# COMPUTE_CLUSTER0_DRU register map
Vendor: Texas Instruments
Peripheral module from a debugger description file (folder am65x).
Registers are 64-bit, read-write, reset 0x0 unless marked. A register's access mark holds for its fields unless they carry their own. Offsets are as the file gives them; lines under a group give offsets from that group; [hi:lo] are bit positions; {n}, {i} and the like mark numbered series; 'fields as' and 'values as' point back to an identical list; <NAME> marks a mode.

## COMPUTE_CLUSTER0_DRU
0x00 DRU_PID ro reset 0x662C0900 — Peripheral ID Register
  [31:0] REVISION — PID Revision
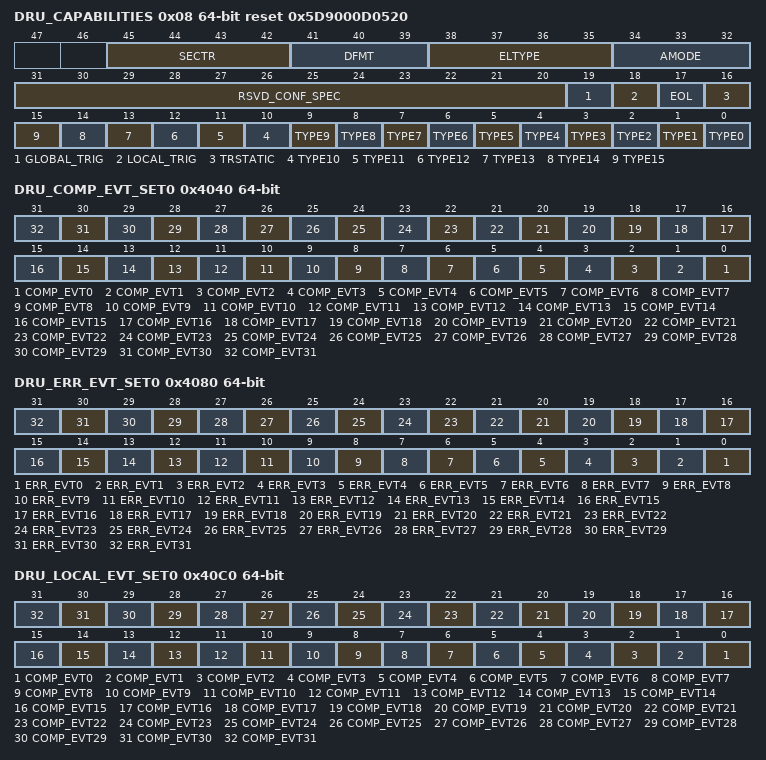
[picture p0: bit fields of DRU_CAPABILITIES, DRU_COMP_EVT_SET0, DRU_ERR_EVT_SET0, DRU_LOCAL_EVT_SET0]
0x08 DRU_CAPABILITIES ro reset 0x5D9000D0520 — DRU Capabilities: Lists the capabilities of the channel for TR TYPE and formatting functions
  [45:42] SECTR — Maximum second TR function that is supported
  [41:39] DFMT — Maximum data reformatting function that is supported
  [38:35] ELTYPE — Maximum element type value that is supported
  [34:32] AMODE — The maximum AMODE that is supported. If AMODE is supported then DIR field must be supported for that AMODE.
  [31:20] RSVD_CONF_SPEC — Reserved for Configuration Specific Features. This implementation has no configuration specific features.
  [19] GLOBAL_TRIG — Global Triggers 0 and 1 are supported
  [18] LOCAL_TRIG — Dedicated Local Trigger is supported
  [17] EOL — EOL Field is supported
  [16] TRSTATIC — STATIC Field is supported
  [n] TYPE{n} (n=0..15) — Type {n} TR is supported
0x4000 DRU_SHARED_EVT_SET access per field — DRU Shared Event Set Register
  [0] PROT_ERR wo — Set the protocol error event
0x4040 DRU_COMP_EVT_SET0 wo — DRU Completion Event Set Register
  [n] COMP_EVT{n} (n=0..31) — Set the Completion Event for channel {n}
0x4080 DRU_ERR_EVT_SET0 wo — DRU Error Event Set Register
  [n] ERR_EVT{n} (n=0..31) — Set the Error Event for channel {n}
0x40C0 DRU_LOCAL_EVT_SET0 wo — DRU Local Event Set Register
  [n] COMP_EVT{n} (n=0..31) — Set the Local Event for channel {n}
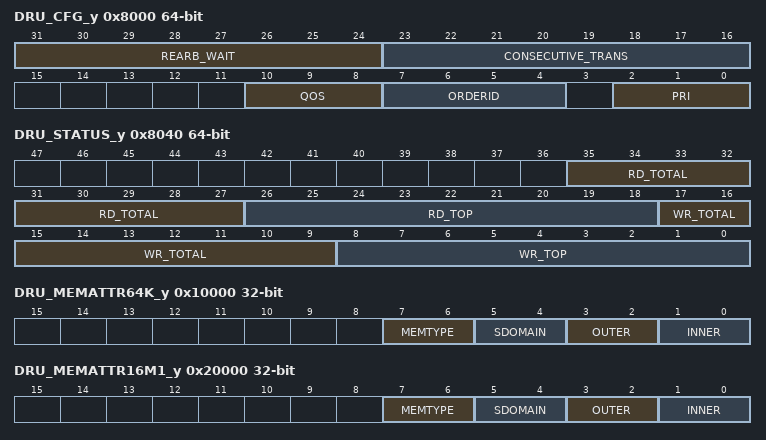
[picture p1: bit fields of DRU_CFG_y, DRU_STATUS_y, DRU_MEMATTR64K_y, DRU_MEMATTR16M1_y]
0x8000 DRU_CFG_y access per field — Configuration Register for Queue 'y' Offset = 8000h + (y * 8h); where y = 0h to 4h
  [31:24] REARB_WAIT rw — This is the number of commands that will be sent by other queues before allowing the queue to arbitrate again for the right to send commands. This is only started when a queue exhausted its consecutive trans count.
  [23:16] CONSECUTIVE_TRANS rw — This is the number of consecutive transactions that will be sent before allowing another queue of equal level to arbitrate to send commands. This is the maximum number of commands that it can send. If the queue has any delays such as virtual address lookup then the arbitration will be forced regardless of the number of commands.
  [10:8] QOS rw — This configures the QoS for Queue 'y'. This should only be set for fixed priority queues and the lower queue should have the lower QoS.
  [7:4] ORDERID rw — This configures the Order ID for Queue 'y'.
  [2:0] PRI rw — This configures the priority for Queue 'y'. This will be the priority that will be presented on the External bus for all commands from this queue.
0x8040 DRU_STATUS_y ro — Status Register for Queue 'y' Offset = 8040h + (y * 8h); where y = 0h to 4h
  [35:27] RD_TOTAL — This is the channel that the read half is currently working on.
  [26:18] RD_TOP — This is the channel that the read half is currently working on.
  [17:9] WR_TOTAL — This is the channel that the write half is currently working on.
  [8:0] WR_TOP — This is the channel that the write half is currently working on.
0x10000 DRU_MEMATTR64K_y 32-bit — The Memory Attribute register contains the attributes for all the 64K mapped regions. Offset = 10000h + (y * 4h); where y = 0h to 7Fh
  [7:6] MEMTYPE — Defines the type of the memory
  [5:4] SDOMAIN — Defines the shareability domain of the memory
  [3:2] OUTER — Defines the outer allocatability of the memory
  [1:0] INNER — Defines the inner allocatability of the memory
0x20000 DRU_MEMATTR16M1_y 32-bit — The Memory Attribute register contains the attributes for all the second 16M mapped regions. Offset = 20000h + (y * 4h); where y = 0h to 7FFh
  fields as DRU_MEMATTR64K_y
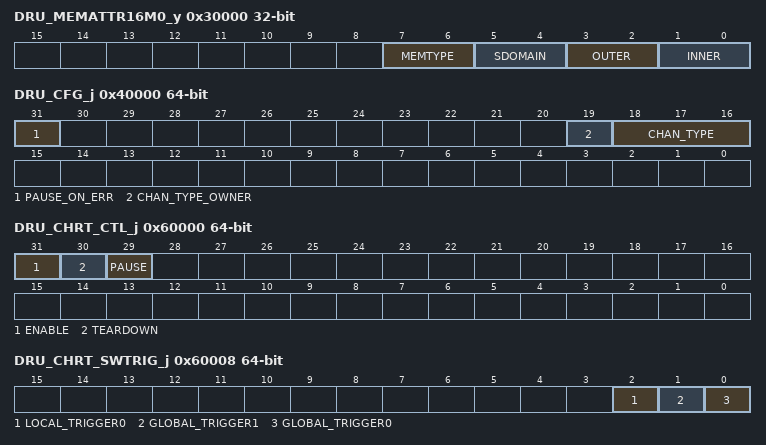
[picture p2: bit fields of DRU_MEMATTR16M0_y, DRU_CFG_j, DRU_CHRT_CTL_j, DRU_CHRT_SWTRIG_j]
0x30000 DRU_MEMATTR16M0_y 32-bit — The Memory Attribute register contains the attributes for all the first 16M mapped regions. Offset = 30000h + (y * 4h); where y = 0h to 7Fh
  fields as DRU_MEMATTR64K_y
0x40000 DRU_CFG_j access per field — Channel Configuration Register. The Channel Configuration Register is used to initialize static mode settings for the DMA Channel. The register may only be written when the chanel is disable by setting to 0x0 the DRU_CHRT_CTL_j[31] ENABLE bit. Offset = 40000h + (j * 100h); where j = 0h to 1Fh
  [31] PAUSE_ON_ERR rw — Pause on Error. This field controls what the channel will do if an error or exception occurs during a data transfer. This field is encoded as follows:0 = Channel will drop current work and move on1 = Channel will pause and wait for SW to investigate and un-pause the channel.
  [19] CHAN_TYPE_OWNER rw — This field controls how the TR is received by the UTC.0 = The DRU_SUBMIT_WORD0_1_j_k to DRU_SUBMIT_WORD14_15_j_k registers must be written to submit it.1 = The TR will be received through PSI-L.
  [18:16] CHAN_TYPE ro — This field states the TR type that is being used along with CHAN_TYPE_OWNER field make up the 4-bit CHAN_TYPE for an UTC. The value of this is all zeroes to reflect that the UTC DRU only does TRs through pass-by value mechanisms.
0x40020 DRU_CHOES0_j access per field — The Output Event Steering Registers are used to specify a global event number to generate anytime the required event generation criteria specified in a TR are met. A single event with the event number set equal to the value in the corresponding register will be generated. This register is provided in order to allow security software to lock down which events in the global space any given channel/ thread is allowed to generate Offset = 40020h + (j * 100h); where j = 0h to 1Fh
  [15:0] EVT_NUM rw — This is the global event number to be generated.
0x40060 DRU_CHST_SCHED_j — Channel Static Scheduler Config Register Offset = 40060h + (j * 100h); where j = 0h to 1Fh
  [2:0] QUEUE — Thus is the queue number that is written
0x60000 DRU_CHRT_CTL_j access per field — The channel realtime control register contains real-time cotrol and status information for the DMA Channel. The fields in this regsiter can be changed while the channel is in operation. Offset = 60000h + (j * 100h); where j = 0h to 1Fh
  [31] ENABLE rw — This field enables or disables the channel. Disabling a channel halts operation on the channel after the current block transfer is completed. Disabling a channel in the middle of a packet transfer may result in underflow conditions in the attached application block and data loss. This field will be cleared after a channel teardown is complete. This field is encoded as follows:0 = channel is disabled1 = channel is enabled
  [30] TEARDOWN rw — Channel teardown.Setting this bit will request the channel to be torn down. This field will remain set after a channel teardown is complete.
  [29] PAUSE rw — Channel pause.Setting this bit will request the channel to pause processing at the next packet boundary. This is a more graceful method of halting processing than disabling the channel as it will not allow any current packets to underflow.
0x60008 DRU_CHRT_SWTRIG_j access per field — The Software Trigger Register provides a mechanism by which software can directly trigger the channel in a secure way. Offset = 60008h + (j * 100h); where j = 0h to 1Fh
  [2] LOCAL_TRIGGER0 rw — Trigger: writing this bit with a value of 1 will cause the trigger event to be sent to this channel. This will trigger Local Event
  [1] GLOBAL_TRIGGER1 rw — Trigger: writing this bit with a value of 1 will cause the trigger event to be sent to this channel. This will trigger Global Event 1
  [0] GLOBAL_TRIGGER0 rw — Trigger: writing this bit with a value of 1 will cause the trigger event to be sent to this channel. This will trigger Global Event 0
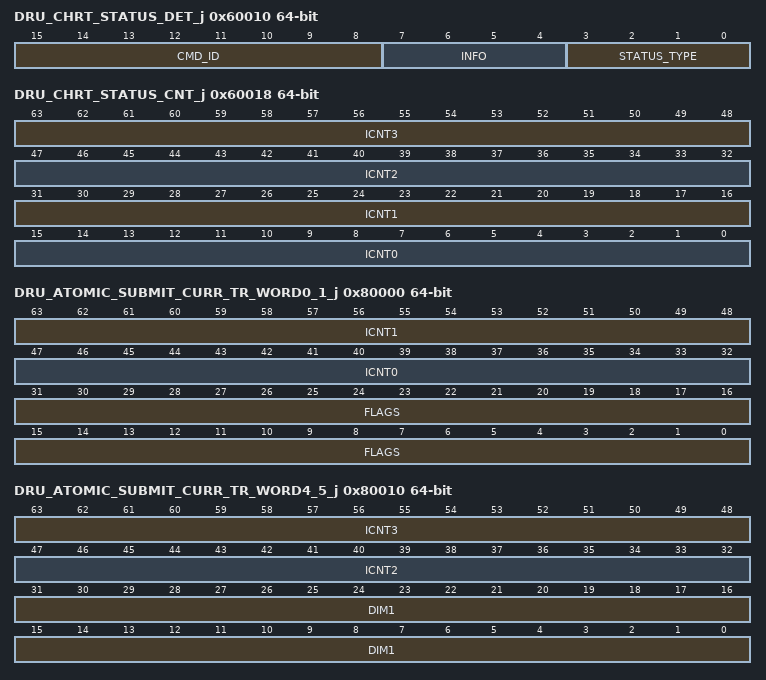
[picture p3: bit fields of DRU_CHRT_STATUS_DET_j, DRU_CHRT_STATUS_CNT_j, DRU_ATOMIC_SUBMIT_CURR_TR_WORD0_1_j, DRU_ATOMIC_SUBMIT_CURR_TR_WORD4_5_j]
0x60010 DRU_CHRT_STATUS_DET_j ro — The channel status details Offset = 60010h + (j * 100h); where j = 0h to 1Fh
  [15:8] CMD_ID — The command id of the TR that had an error.
  [7:4] INFO — The information of the type of status.
  [3:0] STATUS_TYPE — The type of error that occured. Submission Errors are not captured in this register
0x60018 DRU_CHRT_STATUS_CNT_j ro — The channel count details Offset = 60018h + (j * 100h); where j = 0h to 1Fh
  [63:48] ICNT3 — Value of outermost count when error occurred
  [47:32] ICNT2 — Value of second outermost count when error occurred
  [31:16] ICNT1 — The value of the second innermost count when error occurred
  [15:0] ICNT0 — The value of the innermost count when error occurred
0x80000 DRU_ATOMIC_SUBMIT_CURR_TR_WORD0_1_j — The first TR submission word Offset = 80000h + (j * 100h); where j = 0h to 1Fh
  [63:48] ICNT1 — Lines in a transfer
  [47:32] ICNT0 — Bytes in a transfer
  [31:0] FLAGS — Flags for the operation and type of descriptor
0x80008 DRU_ATOMIC_SUBMIT_CURR_TR_WORD2_3_j access per field — The second TR submission word Offset = 80008h + (j * 100h); where j = 0h to 1Fh
  [47:0] SRC_ADDR rw — Source transfer address virtual or physical allowed
0x80010 DRU_ATOMIC_SUBMIT_CURR_TR_WORD4_5_j — The third TR submission word Offset = 80010h + (j * 100h); where j = 0h to 1Fh
  [63:48] ICNT3 — The size of the 4th loop in the TR transfer
  [47:32] ICNT2 — The size of the 3rd loop in the TR transfer
  [31:0] DIM1 — The first dimension width of the source data
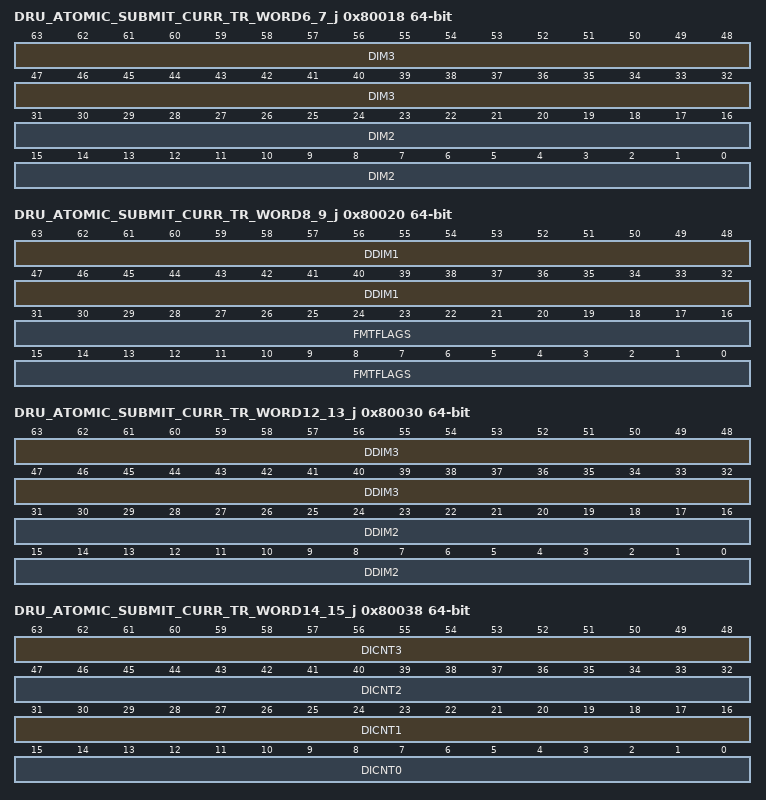
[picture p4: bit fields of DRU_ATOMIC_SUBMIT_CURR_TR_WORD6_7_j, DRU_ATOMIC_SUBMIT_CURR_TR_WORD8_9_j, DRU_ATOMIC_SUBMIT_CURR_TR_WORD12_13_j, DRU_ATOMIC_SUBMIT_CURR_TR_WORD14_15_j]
0x80018 DRU_ATOMIC_SUBMIT_CURR_TR_WORD6_7_j — The fourth TR submission word Offset = 80018h + (j * 100h); where j = 0h to 1Fh
  [63:32] DIM3 — The third dimension width of the source data
  [31:0] DIM2 — The second dimension width of the source data
0x80020 DRU_ATOMIC_SUBMIT_CURR_TR_WORD8_9_j — The fifth TR submission word Offset = 80020h + (j * 100h); where j = 0h to 1Fh
  [63:32] DDIM1 — The first dimension width of the destination data
  [31:0] FMTFLAGS — The data formatting flags to be used for the TR
0x80028 DRU_ATOMIC_SUBMIT_CURR_TR_WORD10_11_j access per field — The sixth TR submission word Offset = 80028h + (j * 100h); where j = 0h to 1Fh
  [47:0] DADDR rw — Destination transfer address virtual or physical allowed
0x80030 DRU_ATOMIC_SUBMIT_CURR_TR_WORD12_13_j — The seventh TR submission word Offset = 80030h + (j * 100h); where j = 0h to 1Fh
  [63:32] DDIM3 — The third dimension width of the destination data
  [31:0] DDIM2 — The second dimension width of the destination data
0x80038 DRU_ATOMIC_SUBMIT_CURR_TR_WORD14_15_j — The eight TR submission word Offset = 80038h + (j * 100h); where j = 0h to 1Fh
  [63:48] DICNT3 — The fourth count of the destination if different than the source
  [47:32] DICNT2 — The third count of the destination if different than the source
  [31:16] DICNT1 — The second innermost count of the destination if different than the source
  [15:0] DICNT0 — The innermost count of the destination if different than the source
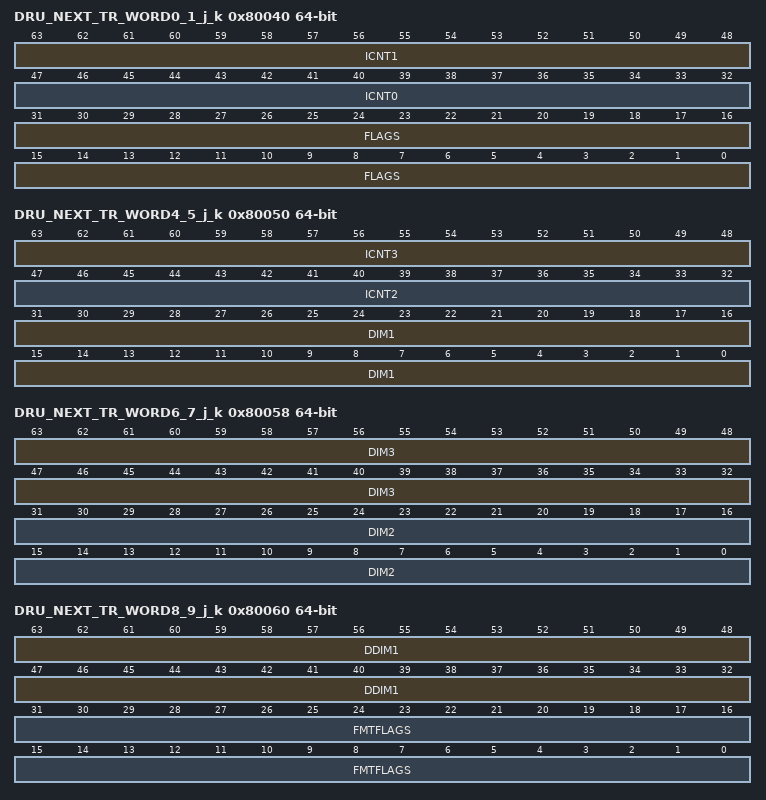
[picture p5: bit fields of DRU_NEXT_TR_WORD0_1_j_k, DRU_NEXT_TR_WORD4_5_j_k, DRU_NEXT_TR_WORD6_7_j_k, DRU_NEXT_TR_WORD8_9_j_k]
0x80040 DRU_NEXT_TR_WORD0_1_j_k ro — The first TR submission word Offset = 80040h + (j * 100h) + (k * 40h); where j = 0h to 1Fh, k = 0h to 2h
  fields as DRU_ATOMIC_SUBMIT_CURR_TR_WORD0_1_j
0x80048 DRU_NEXT_TR_WORD2_3_j_k ro — The second TR submission word Offset = 80048h + (j * 100h) + (k * 40h); where j = 0h to 1Fh, k = 0h to 2h
  [47:0] SRC_ADDR — Source transfer address virtual or physical allowed
0x80050 DRU_NEXT_TR_WORD4_5_j_k ro — The third TR submission word Offset = 80050h + (j * 100h) + (k * 40h); where j = 0h to 1Fh, k = 0h to 2h
  fields as DRU_ATOMIC_SUBMIT_CURR_TR_WORD4_5_j
0x80058 DRU_NEXT_TR_WORD6_7_j_k ro — The fourth TR submission word Offset = 80058h + (j * 100h) + (k * 40h); where j = 0h to 1Fh, k = 0h to 2h
  fields as DRU_ATOMIC_SUBMIT_CURR_TR_WORD6_7_j
0x80060 DRU_NEXT_TR_WORD8_9_j_k ro — The fifth TR submission word Offset = 80060h + (j * 100h) + (k * 40h); where j = 0h to 1Fh, k = 0h to 2h
  fields as DRU_ATOMIC_SUBMIT_CURR_TR_WORD8_9_j
0x80068 DRU_NEXT_TR_WORD10_11_j_k ro — The sixth TR submission word Offset = 80068h + (j * 100h) + (k * 40h); where j = 0h to 1Fh, k = 0h to 2h
  [47:0] DADDR — Destination transfer address virtual or physical allowed
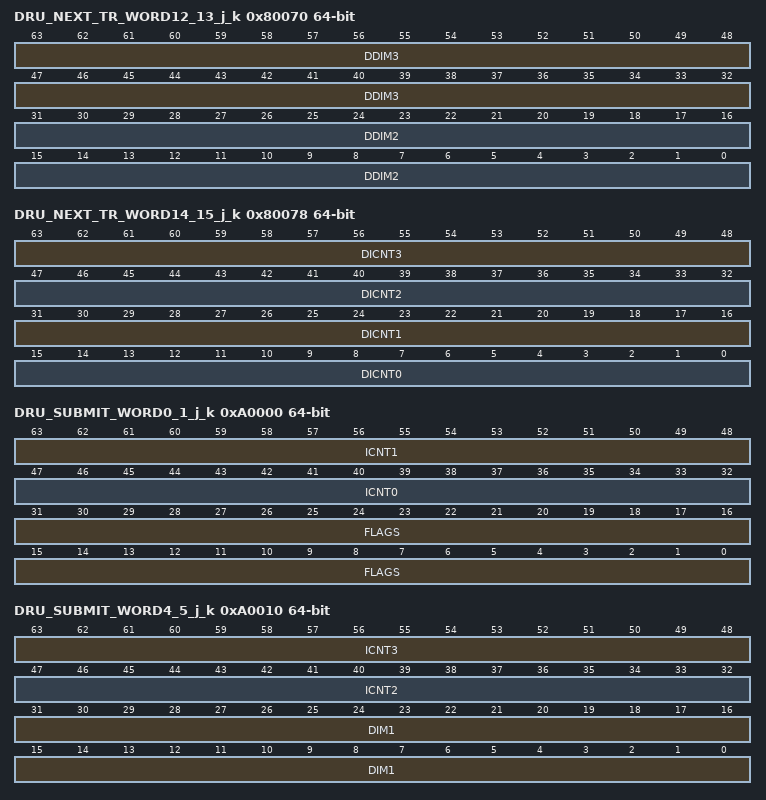
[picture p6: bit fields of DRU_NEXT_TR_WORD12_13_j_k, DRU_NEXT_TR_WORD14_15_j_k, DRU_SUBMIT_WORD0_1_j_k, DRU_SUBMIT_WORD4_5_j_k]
0x80070 DRU_NEXT_TR_WORD12_13_j_k ro — The seventh TR submission word Offset = 80070h + (j * 100h) + (k * 40h); where j = 0h to 1Fh, k = 0h to 2h
  fields as DRU_ATOMIC_SUBMIT_CURR_TR_WORD12_13_j
0x80078 DRU_NEXT_TR_WORD14_15_j_k ro — The eight TR submission word Offset = 80078h + (j * 100h) + (k * 40h); where j = 0h to 1Fh, k = 0h to 2h
  fields as DRU_ATOMIC_SUBMIT_CURR_TR_WORD14_15_j
0xA0000 DRU_SUBMIT_WORD0_1_j_k — The first TR submission word Offset = A0000h + (j * 100h) + (k * 40h); where j = 0h to 1Fh, k = 0h to 2h
  fields as DRU_ATOMIC_SUBMIT_CURR_TR_WORD0_1_j
0xA0008 DRU_SUBMIT_WORD2_3_j_k access per field — The second TR submission word Offset = A0008h + (j * 100h) + (k * 40h); where j = 0h to 1Fh, k = 0h to 2h
  fields as DRU_ATOMIC_SUBMIT_CURR_TR_WORD2_3_j
0xA0010 DRU_SUBMIT_WORD4_5_j_k — The third TR submission word Offset = A0010h + (j * 100h) + (k * 40h); where j = 0h to 1Fh, k = 0h to 2h
  fields as DRU_ATOMIC_SUBMIT_CURR_TR_WORD4_5_j
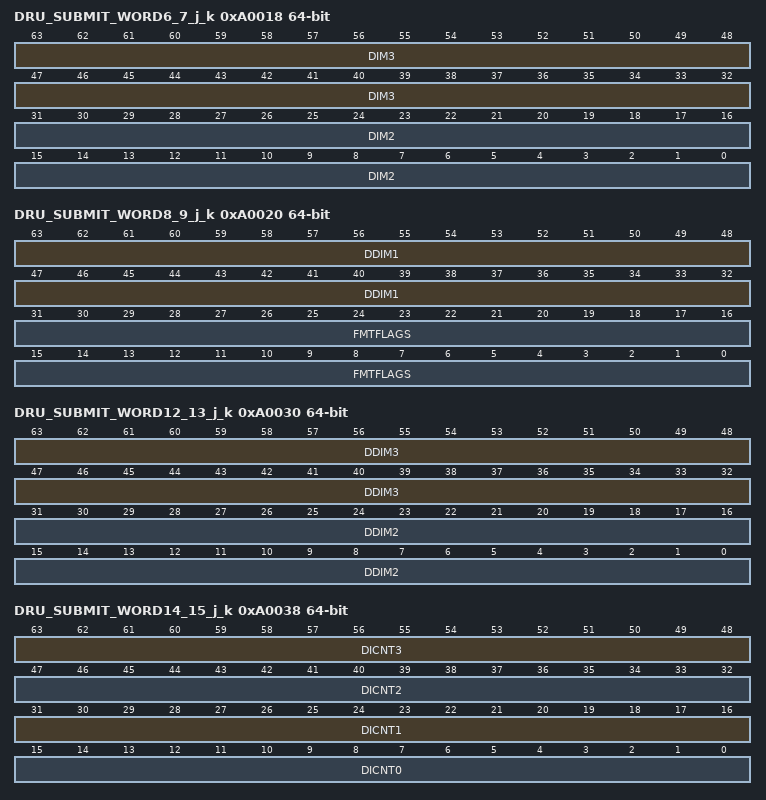
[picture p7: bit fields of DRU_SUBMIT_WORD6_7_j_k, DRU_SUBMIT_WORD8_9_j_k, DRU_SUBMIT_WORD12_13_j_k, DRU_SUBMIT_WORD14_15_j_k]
0xA0018 DRU_SUBMIT_WORD6_7_j_k — The fourth TR submission word Offset = A0018h + (j * 100h) + (k * 40h); where j = 0h to 1Fh, k = 0h to 2h
  fields as DRU_ATOMIC_SUBMIT_CURR_TR_WORD6_7_j
0xA0020 DRU_SUBMIT_WORD8_9_j_k — The fifth TR submission word Offset = A0020h + (j * 100h) + (k * 40h); where j = 0h to 1Fh, k = 0h to 2h
  fields as DRU_ATOMIC_SUBMIT_CURR_TR_WORD8_9_j
0xA0028 DRU_SUBMIT_WORD10_11_j_k access per field — The sixth TR submission word Offset = A0028h + (j * 100h) + (k * 40h); where j = 0h to 1Fh, k = 0h to 2h
  fields as DRU_ATOMIC_SUBMIT_CURR_TR_WORD10_11_j
0xA0030 DRU_SUBMIT_WORD12_13_j_k — The seventh TR submission word Offset = A0030h + (j * 100h) + (k * 40h); where j = 0h to 1Fh, k = 0h to 2h
  fields as DRU_ATOMIC_SUBMIT_CURR_TR_WORD12_13_j
0xA0038 DRU_SUBMIT_WORD14_15_j_k — The eight TR submission word Offset = A0038h + (j * 100h) + (k * 40h); where j = 0h to 1Fh, k = 0h to 2h
  fields as DRU_ATOMIC_SUBMIT_CURR_TR_WORD14_15_j
0xE0000 DRU_CAUSE_y ro — Offset = E0000h + (y * 8h); where y = 0h to 1h
  [4n+3] R_ERR{n} (n=1..15) — Masked error bit for Tx channel 16*y+{n}
  [4n+2] R_PEND{n} (n=1..15) — Masked completion ring pending bit for Rx channel 16*y+{n}
  [4n+1] T_ERR{n} (n=1..15) — Masked error bit for Tx channel 16*y+{n}
  [4n] T_PEND{n} (n=1..15) — Masked completion ring pending bit for Tx channel 16*y+{n}
  [3] R_ERR0 — Masked error bit for Tx channel 16*y
  [2] R_PEND0 — Masked completion ring pending bit for Rx channel 16*y
  [1] T_ERR0 — Masked error bit for Tx channel 16*y
  [0] T_PEND0 — Masked completion ring pending bit for Tx channel 16*y
